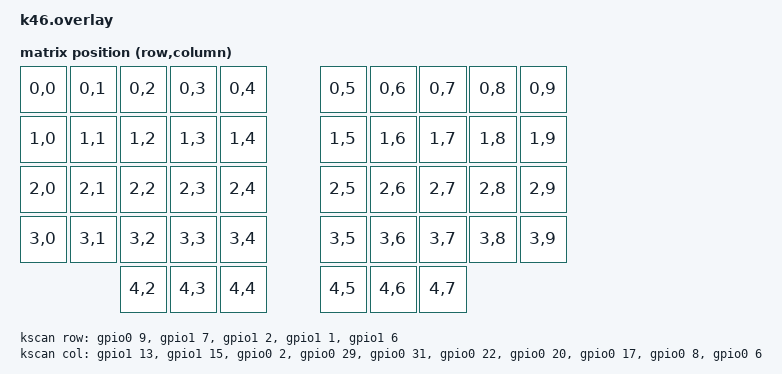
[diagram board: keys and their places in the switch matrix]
// This file was generated from a template. Edit it to match your keyboard.
// See https://zmk.dev/docs/development/hardware-integration/new-shield for more
// instructions.

#include <dt-bindings/zmk/matrix_transform.h>
#include "k46-layouts.dtsi"
#include "k46_oled.dtsi"

/ {
    chosen {
        zephyr,display = &oled;
        zmk,physical-layout = &default_layout;
    };

    kscan: kscan {
        // If the hardware does not use a switch matrix, change this to the
        // appropriate driver and update the properties below to match.
        // See https://zmk.dev/docs/config/kscan for supported key scan drivers.
        compatible = "zmk,kscan-gpio-matrix";
        // Set this to "col2row" or "row2col" to match the hardware. If using
        // "row2col", change the col-gpios to (GPIO_ACTIVE_HIGH | GPIO_PULL_DOWN)
        // and the row-gpios to GPIO_ACTIVE_HIGH.
        diode-direction = "col2row";
        wakeup-source;

        // Replace these comments with the GPIO pins in the matrix.        
        // See https://zmk.dev/docs/development/hardware-integration/new-shield#shield-overlays

        col-gpios
            = <&gpio1 13 GPIO_ACTIVE_HIGH> // 113  col1
            , <&gpio1 15 GPIO_ACTIVE_HIGH> // 115 col2
            , <&gpio0 2 GPIO_ACTIVE_HIGH> // 002  col3
            , <&gpio0 29 GPIO_ACTIVE_HIGH> // 029  col4
            , <&gpio0 31 GPIO_ACTIVE_HIGH> // 031  col5
            , <&gpio0 22 GPIO_ACTIVE_HIGH> // 022 col6
            , <&gpio0 20 GPIO_ACTIVE_HIGH> // 020  col7
            , <&gpio0 17 GPIO_ACTIVE_HIGH> // 017  col8
            , <&gpio0 8 GPIO_ACTIVE_HIGH> // 008   col9
            , <&gpio0 6 GPIO_ACTIVE_HIGH> // 006  col10
            ;

        row-gpios
            = <&gpio0 9 (GPIO_ACTIVE_HIGH | GPIO_PULL_DOWN)> // 009 row1
            , <&gpio1 7 (GPIO_ACTIVE_HIGH | GPIO_PULL_DOWN)> // 107 row2
            , <&gpio1 2 (GPIO_ACTIVE_HIGH | GPIO_PULL_DOWN)> // 102 row3
            , <&gpio1 1 (GPIO_ACTIVE_HIGH | GPIO_PULL_DOWN)> // 101 row4
            , <&gpio1 6 (GPIO_ACTIVE_HIGH | GPIO_PULL_DOWN)> // 106 row5
            ;
    };

    default_transform: default_transform {
        // See https://zmk.dev/docs/development/hardware-integration/new-shield#matrix-transform
        // for how to configure this
        compatible = "zmk,matrix-transform";
          columns = <10>;
        rows = <5>;
        map = <
            RC(0,0) RC(0,1) RC(0,2) RC(0,3) RC(0,4)     RC(0,5) RC(0,6) RC(0,7) RC(0,8) RC(0,9)
            RC(1,0) RC(1,1) RC(1,2) RC(1,3) RC(1,4)     RC(1,5) RC(1,6) RC(1,7) RC(1,8) RC(1,9)
            RC(2,0) RC(2,1) RC(2,2) RC(2,3) RC(2,4)     RC(2,5) RC(2,6) RC(2,7) RC(2,8) RC(2,9)
            RC(3,0) RC(3,1) RC(3,2) RC(3,3) RC(3,4)     RC(3,5) RC(3,6) RC(3,7) RC(3,8) RC(3,9)
                            RC(4,2) RC(4,3) RC(4,4)     RC(4,5) RC(4,6) RC(4,7) 
        >;
    };
};
